# LIS331EB register map
Vendor: STMicroelectronics; Series: LIS331EB; File version: 1.0
CPU: CM0 r0p0, little endian, no MPU, no FPU, 5 interrupt priority bits
Registers are 32-bit, read-write, reset 0x0 unless marked. A register's access mark holds for its fields unless they carry their own. Offsets are from the block's base; [hi:lo] are bit positions; {n}, {i} and the like mark numbered series; 'fields as' and 'values as' point back to an identical list; <NAME> marks a mode.

## UART — PrimeCell UART (PL011)
Base 0xA2000000
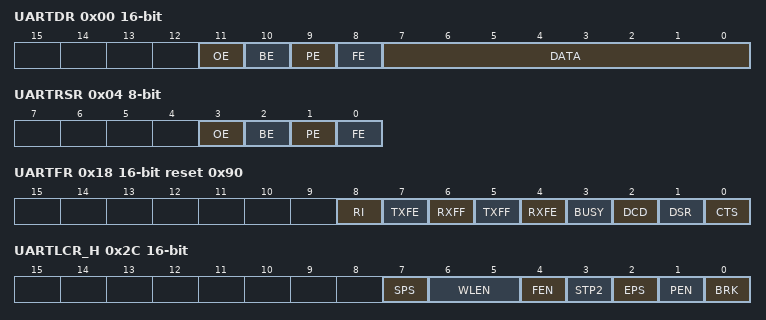
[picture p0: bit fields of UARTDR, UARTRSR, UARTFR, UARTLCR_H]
0x00 UARTDR 16-bit — Data Register
  [11] OE ro — Overrun error
  [10] BE ro — Break error
  [9] PE ro — Parity error
  [8] FE ro — Framing error
  [7:0] DATA — Receive (read) data character / Transmit (write) data character
0x04 UARTRSR 8-bit ro — Receive Status Register
  [3] OE — Overrun error
  [2] BE — Break error
  [1] PE — Parity error
  [0] FE — Framing error
0x04 UARTECR 8-bit (alternate view of UARTRSR) — Error Clear Register
0x18 UARTFR 16-bit ro reset 0x90 — Flag Register
  [8] RI — Ring indicator
  [7] TXFE — Transmit FIFO empty
  [6] RXFF — Receive FIFO full
  [5] TXFF — Transmit FIFO full
  [4] RXFE — Receive FIFO empty
  [3] BUSY — UART Busy
  [2] DCD — Data carrier detect
  [1] DSR — Data set ready
  [0] CTS — Clear to send
0x20 UARTILPR 8-bit — IrDA Low-Power Counter Register
  [7:0] ILPDVSR — 8-bit low-power divisor value
0x24 UARTIBRD 16-bit — Integer Baud Rate Register
  [15:0] BAUD_DIVINT — The integer baud rate divisor
0x28 UARTFBRD 8-bit — Fractional Baud Rate Register
  [5:0] BAUD_DIVFRAC — The fractional baud rate divisor
0x2C UARTLCR_H 16-bit — Line Control Register
  [7] SPS — Stick parity check
  [6:5] WLEN — Word length
    {v}={v+5} bits (v=0..3)
  [4] FEN — Enable FIFOs
  [3] STP2 — Two stop bits select
  [2] EPS — Even parity select
    0=ODD (Odd Parity); 1=EVEN (Even Parity)
  [1] PEN — Parity enable
  [0] BRK — Send break
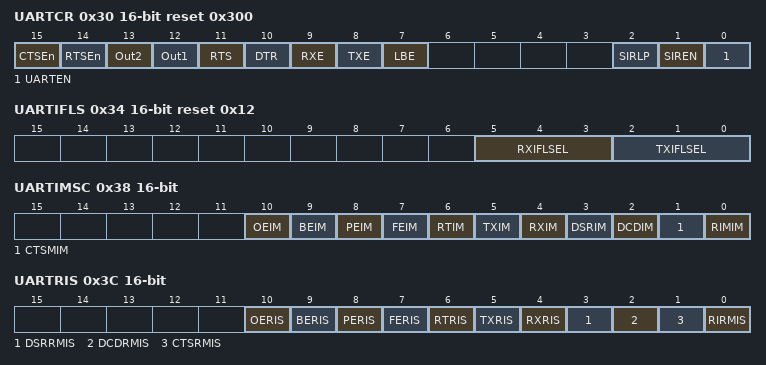
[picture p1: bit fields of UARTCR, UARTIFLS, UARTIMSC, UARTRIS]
0x30 UARTCR 16-bit reset 0x300 — Control Register
  [15] CTSEn — CTS hardware flow control enable
  [14] RTSEn — RTS hardware flow control enable
  [13] Out2 — This bit is the complement of the UART Out2 modem status output
  [12] Out1 — This bit is the complement of the UART Out1 modem status output
  [11] RTS — Request to send
  [10] DTR — Data transmit ready
  [9] RXE — Receive enable
  [8] TXE — Transmit enable
  [7] LBE — Loopback enable
  [2] SIRLP — SIR low-power IrDA mode
  [1] SIREN — SIR enable
  [0] UARTEN — UART enable
0x34 UARTIFLS 16-bit reset 0x12 — Interrupt FIFO Level Select Register
  [5:3] RXIFLSEL — Receive interrupt FIFO level select
    0=1_8 (Interrupt when FIFO <= 1/8 full); 1=1_4 (Interrupt when FIFO <= 1/4 full); 2=1_2 (Interrupt when FIFO <= 1/2 full); 3=3_4 (Interrupt when FIFO <= 3/4 full); 4=7_8 (Interrupt when FIFO <= 7/8 full)
  [2:0] TXIFLSEL — Transmit interrupt FIFO level select
    values as RXIFLSEL
0x38 UARTIMSC 16-bit — Interrupt Mask Set/Clear Register
  [10] OEIM — Overrun error interrupt mask
  [9] BEIM — Break error interrupt mask
  [8] PEIM — Parity error interrupt mask
  [7] FEIM — Framing error interrupt mask
  [6] RTIM — Receive timeout interrupt mask
  [5] TXIM — Transmit interrupt mask
  [4] RXIM — Receive interrupt mask
  [3] DSRIM — nUARTDRS modem interrupt mask
  [2] DCDIM — nUARTDCD modem interrupt mask
  [1] CTSMIM — nUARTCTS modem interrupt mask
  [0] RIMIM — nUARTRI modem interrupt mask
0x3C UARTRIS 16-bit ro — Raw Interrupt Status Register
  [10] OERIS — Overrun error interrupt status
  [9] BERIS — Break error interrupt status
  [8] PERIS — Parity error interrupt status
  [7] FERIS — Framing error interrupt status
  [6] RTRIS — Receive timeout interrupt status
  [5] TXRIS — Transmit interrupt status
  [4] RXRIS — Receive interrupt status
  [3] DSRRMIS — nUARTDRS modem interrupt status
  [2] DCDRMIS — nUARTDCD modem interrupt status
  [1] CTSRMIS — nUARTCTS modem interrupt status
  [0] RIRMIS — nUARTRI modem interrupt status
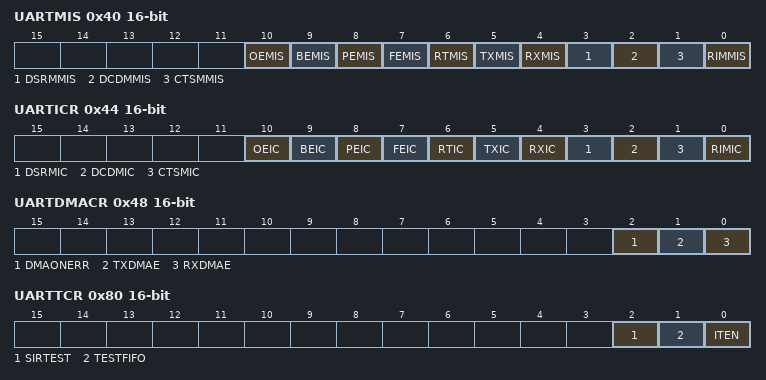
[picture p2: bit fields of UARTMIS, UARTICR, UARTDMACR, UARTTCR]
0x40 UARTMIS 16-bit ro — Masked Interrupt Status Register
  [10] OEMIS — Overrun error masked interrupt status
  [9] BEMIS — Break error masked interrupt status
  [8] PEMIS — Parity error masked interrupt status
  [7] FEMIS — Framing error masked interrupt status
  [6] RTMIS — Receive timeout masked interrupt status
  [5] TXMIS — Transmit masked interrupt status
  [4] RXMIS — Receive masked interrupt status
  [3] DSRMMIS — nUARTDRS modem masked interrupt status
  [2] DCDMMIS — nUARTDCD modem masked interrupt status
  [1] CTSMMIS — nUARTCTS modem masked interrupt status
  [0] RIMMIS — nUARTRI modem masked interrupt status
0x44 UARTICR 16-bit wo — Interrupt Clear Register
  [10] OEIC — Overrun error interrupt clear
  [9] BEIC — Break error interrupt clear
  [8] PEIC — Parity error interrupt clear
  [7] FEIC — Framing error interrupt clear
  [6] RTIC — Receive timeout interrupt clear
  [5] TXIC — Transmit interrupt clear
  [4] RXIC — Receive interrupt clear
  [3] DSRMIC — nUARTDRS modem interrupt clear
  [2] DCDMIC — nUARTDCD modem interrupt clear
  [1] CTSMIC — nUARTCTS modem interrupt clear
  [0] RIMIC — nUARTRI modem interrupt clear
0x48 UARTDMACR 16-bit — DMA Control Register
  [2] DMAONERR — DMA on error
  [1] TXDMAE — Transmit DMA enable
  [0] RXDMAE — Receive DMA enable
0x80 UARTTCR 16-bit — Test Control Register
  [2] SIRTEST — SIR test enable
  [1] TESTFIFO — Test FIFO enable
  [0] ITEN — Integration test enable
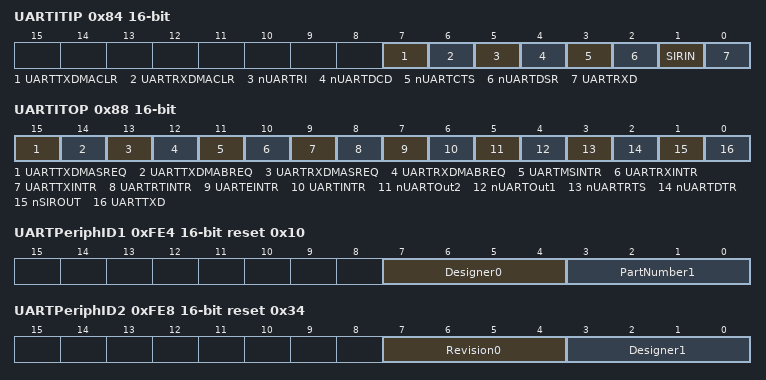
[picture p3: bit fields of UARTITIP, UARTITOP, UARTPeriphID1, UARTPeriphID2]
0x84 UARTITIP 16-bit — Integration Test Input Register
  [7] UARTTXDMACLR — Writes to this bit specify the value to be driven on the intra-chip input, UARTTXDMACLR, in the integration test mode. Reads return the value of UARTTXDMACLR at the output of the test multiplexor
  [6] UARTRXDMACLR — Writes to this bit specify the value to be driven on the intra-chip input, UARTRXDMACLR, in the integration test mode. Reads return the value of UARTRXDMACLR at the output of the test multiplexor
  [5] nUARTRI — Reads return the value of the nUARTRI primary input
  [4] nUARTDCD — Reads return the value of the nUARTDCD primary input
  [3] nUARTCTS — Reads return the value of the nUARTCTS primary input
  [2] nUARTDSR — Reads return the value of the nUARTDSR primary input
  [1] SIRIN — Reads return the value of the SIRIN primary input
  [0] UARTRXD — Reads return the value of the UARTRXD primary input
0x88 UARTITOP 16-bit — Integration Test Output Register
  [15] UARTTXDMASREQ — Writes specify the value to be driven on UARTTXDMASREQ. Reads return the value of UARTTXDMASREQ at the output of the test multiplexor
  [14] UARTTXDMABREQ — Writes specify the value to be driven on UARTTXDMABREQ. Reads return the value of UARTTXDMABREQ at the output of the test multiplexor
  [13] UARTRXDMASREQ — Writes specify the value to be driven on UARTRXDMASREQ. Reads return the value of UARTRXDMASREQ at the output of the test multiplexor
  [12] UARTRXDMABREQ — Writes specify the value to be driven on UARTRXDMABREQ. Reads return the value of UARTRXDMABREQ at the output of the test multiplexor
  [11] UARTMSINTR — Writes specify the value to be driven on UARTMSINTR. Reads return the value of UARTMSINTR at the output of the test multiplexor
  [10] UARTRXINTR — Writes specify the value to be driven on UARTRXINTR. Reads return the value of UARTRXINTR at the output of the test multiplexor
  [9] UARTTXINTR — Writes specify the value to be driven on UARTTXINTR. Reads return the value of UARTTXINTR at the output of the test multiplexor
  [8] UARTRTINTR — Writes specify the value to be driven on UARTRTINTR. Reads return the value of UARTRTINTR at the output of the test multiplexor
  [7] UARTEINTR — Writes specify the value to be driven on UARTEINTR. Reads return the value of UARTEINTR at the output of the test multiplexor
  [6] UARTINTR — Writes specify the value to be driven on UARTINTR. Reads return the value of UARTINTR at the output of the test multiplexor
  [5] nUARTOut2 — Writes specify the value to be driven on nUARTOut2
  [4] nUARTOut1 — Writes specify the value to be driven on nUARTOut1
  [3] nUARTRTS — Writes specify the value to be driven on nUARTRTS
  [2] nUARTDTR — Writes specify the value to be driven on nUARTDTR
  [1] nSIROUT — Writes specify the value to be driven on nSIROUT
  [0] UARTTXD — Writes specify the value to be driven on UARTTXD
0x8C UARTTDR 16-bit — Test Data Register
  [9:0] DATA — When the TESTFIFO bit is set to 1, data is written into the receive FIFO and read out of the transmit FIFO
0xFE0 UARTPeriphID0 16-bit ro reset 0x11
  [7:0] PartNumber0 — These bits read back as 0x11
0xFE4 UARTPeriphID1 16-bit ro reset 0x10
  [7:4] Designer0 — These bits read back as 0x1
  [3:0] PartNumber1 — These bits read back as 0x0
0xFE8 UARTPeriphID2 16-bit ro reset 0x34
  [7:4] Revision0 — These bits read back as 0x3
  [3:0] Designer1 — These bits read back as 0x4
0xFEC UARTPeriphID3 16-bit ro
  [7:0] Configuration — These bits read back as 0x00
0xFF0 UARTPCellID0 16-bit ro reset 0xD
  [7:0] UARTPCellID0 — These bits read back as 0x0D
0xFF4 UARTPCellID1 16-bit ro reset 0xF0
  [7:0] UARTPCellID1 — These bits read back as 0xF0
0xFF8 UARTPCellID2 16-bit ro reset 0x5
  [7:0] UARTPCellID2 — These bits read back as 0x05
0xFFC UARTPCellID3 16-bit ro reset 0xB1
  [7:0] UARTPCellID3 — These bits read back as 0xB1
